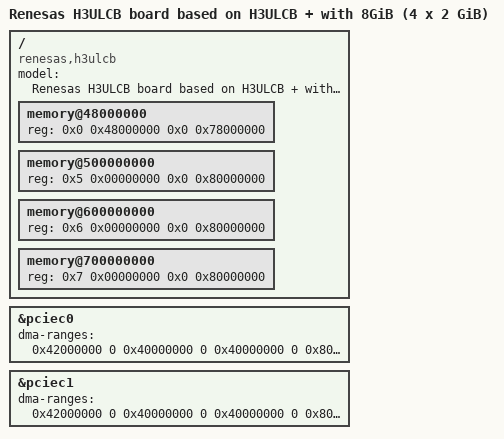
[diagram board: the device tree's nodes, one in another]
/*
 * Device Tree Source for the H3ULCB (R-Car Starter Kit Premier) board
 *
 * Copyright (C) 2018 Renesas Electronics Corp.
 *
 * This file is licensed under the terms of the GNU General Public License
 * version 2. This program is licensed "as is" without any warranty of any
 * kind, whether express or implied.
 */

#include "r8a7795-h3ulcb.dts"

/ {
	model = "Renesas H3ULCB board based on H3ULCB + with 8GiB (4 x 2 GiB)";
	compatible = "renesas,h3ulcb", "renesas,r8a7795";

	memory@48000000 {
		device_type = "memory";
		/* first 128MB is reserved for secure area. */
		reg = <0x0 0x48000000 0x0 0x78000000>;
	};

	memory@500000000 {
		device_type = "memory";
		reg = <0x5 0x00000000 0x0 0x80000000>;
	};

	memory@600000000 {
		device_type = "memory";
		reg = <0x6 0x00000000 0x0 0x80000000>;
	};

	memory@700000000 {
		device_type = "memory";
		reg = <0x7 0x00000000 0x0 0x80000000>;
	};
};

&pciec0 {
	/* Map all possible DDR as inbound ranges */
	dma-ranges = <0x42000000 0 0x40000000 0 0x40000000 0 0x80000000>;
};

&pciec1 {
	/* Map all possible DDR as inbound ranges */
	dma-ranges = <0x42000000 0 0x40000000 0 0x40000000 0 0x80000000>;
};
